VERSION "0.81"

NS_ :

BS_:

BU_:

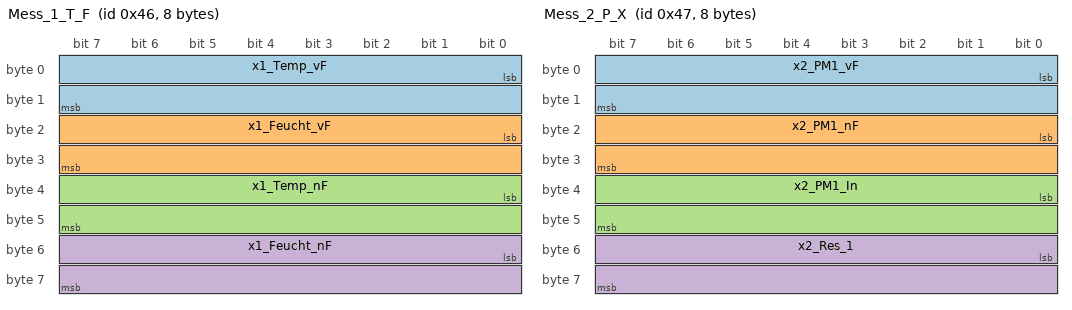
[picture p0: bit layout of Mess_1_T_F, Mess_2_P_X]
BO_ 70 Mess_1_T_F: 8 SM_1
 SG_ x1_Temp_vF : 0|16@1- (1,0) [-1000|1000] "mV"  SM_1
 SG_ x1_Feucht_vF : 16|16@1- (1,0) [-1000|1000] "mV"  SM_1
 SG_ x1_Temp_nF : 32|16@1- (1,0) [-1000|1000] "mV"  SM_1
 SG_ x1_Feucht_nF : 48|16@1- (1,0) [-1000|1000] "mV"  SM_1

BO_ 71 Mess_2_P_X: 8 SM_1
 SG_ x2_PM1_vF : 0|16@1- (1,0) [-1000|1000] "mV"  SM_1
 SG_ x2_PM1_nF : 16|16@1- (1,0) [-1000|1000] "mV"  SM_1
 SG_ x2_PM1_In : 32|16@1- (1,0) [-1000|1000] "mV"  SM_1
 SG_ x2_Res_1 : 48|16@1- (1,0) [-1000|1000] "mV"  SM_1

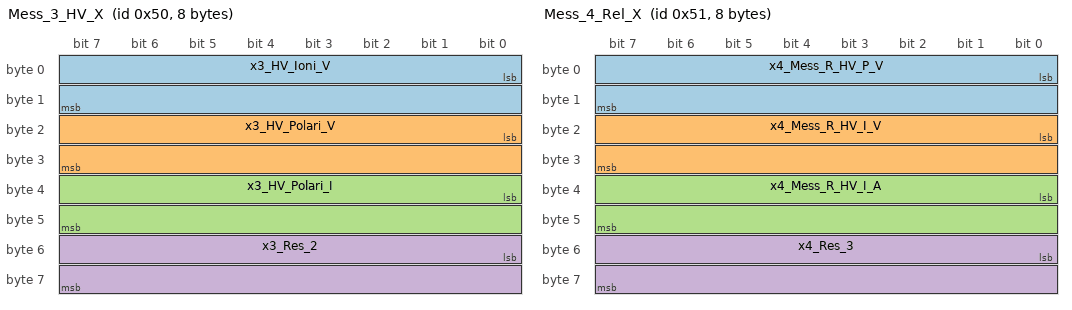
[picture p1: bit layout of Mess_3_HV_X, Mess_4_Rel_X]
BO_ 80 Mess_3_HV_X: 8 SM_2
 SG_ x3_HV_Ioni_V : 0|16@1- (1,0) [-1000|1000] "mV"  SM_2
 SG_ x3_HV_Polari_V : 16|16@1- (1,0) [-1000|1000] "mV"  SM_2
 SG_ x3_HV_Polari_I : 32|16@1- (1,0) [-1000|1000] "mV"  SM_2
 SG_ x3_Res_2 : 48|16@1- (1,0) [-1000|1000] "mV"  SM_2

BO_ 81 Mess_4_Rel_X: 8 SM_2
 SG_ x4_Mess_R_HV_P_V : 0|16@1- (1,0) [-1000|1000] "mV"  SM_2
 SG_ x4_Mess_R_HV_I_V : 16|16@1- (1,0) [-1000|1000] "mV"  SM_2
 SG_ x4_Mess_R_HV_I_A : 32|16@1- (1,0) [0|100] "X"  SM_2
 SG_ x4_Res_3 : 48|16@1- (1,0) [0|100] ""  SM_2
